# STM32H7R7xx register map
File version: 1.0
Registers are 32-bit, read-write, reset 0x0 unless marked. A register's access mark holds for its fields unless they carry their own. Offsets are from the block's base; [hi:lo] are bit positions; lines under a group give offsets from that group; {n}, {i} and the like mark numbered series.

## CRS — Clock Recovery System
Base 0x40008400
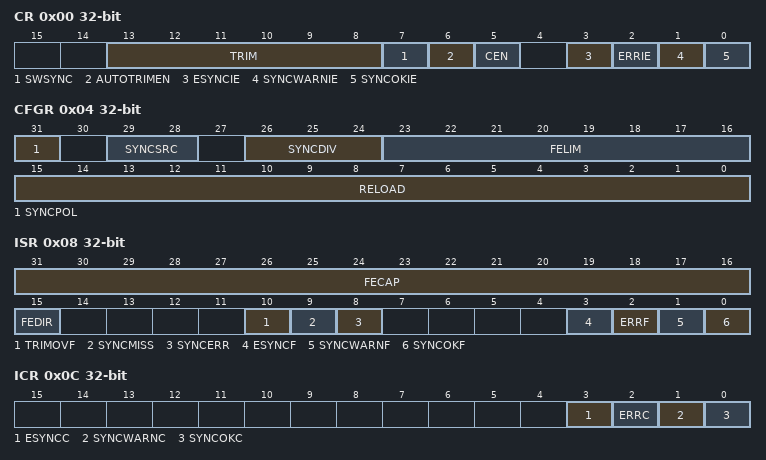
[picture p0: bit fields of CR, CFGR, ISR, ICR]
0x00 CR — CRS ccontrol register
  [13:8] TRIM — HSI48 oscillator smooth trimming
  [7] SWSYNC — Generate software SYNC event
  [6] AUTOTRIMEN — Automatic trimming enable
  [5] CEN — Frequency error counter enable
  [3] ESYNCIE — Expected SYNC interrupt enable
  [2] ERRIE — SYNC error or trimming error interrupt enable
  [1] SYNCWARNIE — SYNC warning interrupt enable
  [0] SYNCOKIE — SYNC event OK interrupt enable
0x04 CFGR — CRS configuration register
  [31] SYNCPOL — SYNC polarity selection
    0=RISING (Synchro Active on rising edge (default)); 1=FALLING (Synchro Active on falling edge)
  [29:28] SYNCSRC — SYNC signal source selection
    0=GPIO (Synchro Signal source GPIO); 1=LSE (Synchro Signal source LSE); 2=OTG_FS (Synchro Signal source OTG_FS SOF (default)); 3=OTG_HS (Synchro Signal source OTG_HS SOF)
  [26:24] SYNCDIV — SYNC divider
    0=DIV_1 (Synchro Signal not divided (default)); 1=DIV_2 (Synchro Signal divided by 2); 2=DIV_4 (Synchro Signal divided by 4); 3=DIV_8 (Synchro Signal divided by 8); 4=DIV_16 (Synchro Signal divided by 16); 5=DIV_32 (Synchro Signal divided by 32); 6=DIV_64 (Synchro Signal divided by 64); 7=DIV_128 (Synchro Signal divided by 128)
  [23:16] FELIM — Frequency error limit
  [15:0] RELOAD — Counter reload value
0x08 ISR — CRS interrupt and status register
  [31:16] FECAP — Frequency error capture
  [15] FEDIR — Frequency error direction
    0=UP (Upcounting direction, the actual frequency is above the target); 1=DOWN (Downcounting direction, the actual frequency is below the target)
  [10] TRIMOVF — Trimming overflow or underflow
  [9] SYNCMISS — SYNC missed
  [8] SYNCERR — SYNC error
  [3] ESYNCF — Expected SYNC flag
  [2] ERRF — Error flag
  [1] SYNCWARNF — SYNC warning flag
  [0] SYNCOKF — SYNC event OK flag
0x0C ICR — CRS interrupt flag clear register
  [3] ESYNCC — Expected SYNC clear flag
  [2] ERRC — Error clear flag
  [1] SYNCWARNC — SYNC warning clear flag
  [0] SYNCOKC — SYNC event OK clear flag

## MDIOS
Base 0x40009400
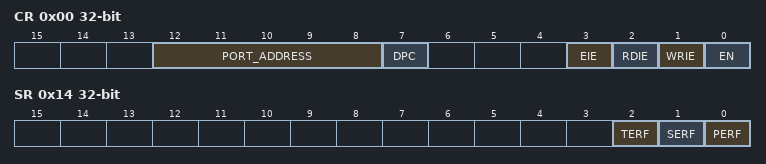
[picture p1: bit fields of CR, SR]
0x00 CR
  [12:8] PORT_ADDRESS — MDIOS slave port address mask
  [7] DPC — MDIOS slave disable preamble check
  [3] EIE — MDIOS slave register error interrupt enable
  [2] RDIE — MDIOS slave register read interrupt enable
  [1] WRIE — MDIOS slave register write interrupt enable
  [0] EN — MDIOS slave peripheral enable
0x04 WRFR
0x08 CWRFR
0x0C RDFR
0x10 CRDFR
0x14 SR
  [2] TERF — MDIOS slave preamble error flag
  [1] SERF — MDIOS slave start error flag
  [0] PERF — MDIOS slave turnaround error flag
0x18 CLRFR
{0x100+4i} DINR{i} (i=0..31)
{0x180+4i} DOUTR{i} (i=0..31)

## FDCAN_CONFIG — FD Controller Area Network Configuration
Base 0x4000A100
0x00 CKDIV — FDCAN clock divider register
  [3:0] PDIV — Input Clock Divider
0x204 OPTR — FDCAN option register
0x2F0 HWCFG — FDCAN hardware configuration register
0x2F4 VERR — FDCAN IP version register
0x2F8 IPIDR — FDCAN IP ID register
0x2FC SIDR — FDCAN size ID register

## ADC12_COMMON
Base 0x40022300
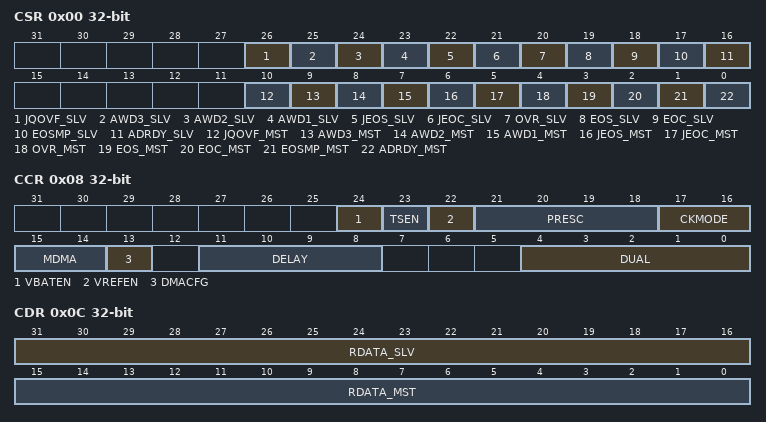
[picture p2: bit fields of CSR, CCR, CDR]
0x00 CSR — ADC common status register
  [26] JQOVF_SLV — ADC multimode slave group injected contexts queue overflow flag
  [25] AWD3_SLV — ADC multimode slave analog watchdog 3 flag
  [24] AWD2_SLV — ADC multimode slave analog watchdog 2 flag
  [23] AWD1_SLV — ADC multimode slave analog watchdog 1 flag
  [22] JEOS_SLV — ADC multimode slave group injected end of sequence conversions flag
  [21] JEOC_SLV — ADC multimode slave group injected end of unitary conversion flag
  [20] OVR_SLV — ADC multimode slave group regular overrun flag
  [19] EOS_SLV — ADC multimode slave group regular end of sequence conversions flag
  [18] EOC_SLV — ADC multimode slave group regular end of unitary conversion flag
  [17] EOSMP_SLV — ADC multimode slave group regular end of sampling flag
  [16] ADRDY_SLV — ADC multimode slave ready flag
  [10] JQOVF_MST — ADC multimode master group injected contexts queue overflow flag
  [9] AWD3_MST — ADC multimode master analog watchdog 3 flag
  [8] AWD2_MST — ADC multimode master analog watchdog 2 flag
  [7] AWD1_MST — ADC multimode master analog watchdog 1 flag
  [6] JEOS_MST — ADC multimode master group injected end of sequence conversions flag
  [5] JEOC_MST — ADC multimode master group injected end of unitary conversion flag
  [4] OVR_MST — ADC multimode master group regular overrun flag
  [3] EOS_MST — ADC multimode master group regular end of sequence conversions flag
  [2] EOC_MST — ADC multimode master group regular end of unitary conversion flag
  [1] EOSMP_MST — ADC multimode master group regular end of sampling flag
  [0] ADRDY_MST — ADC multimode master ready flag
0x08 CCR — ADC common configuration register
  [24] VBATEN — ADC internal path to battery voltage enable
  [23] TSEN — ADC internal path to temperature sensor enable
  [22] VREFEN — ADC internal path to VrefInt enable
  [21:18] PRESC — ADC common clock prescaler, only for clock source asynchronous
  [17:16] CKMODE — ADC common clock source and prescaler (prescaler only for clock source synchronous)
  [15:14] MDMA — ADC multimode DMA transfer enable
  [13] DMACFG — ADC multimode DMA transfer configuration
  [11:8] DELAY — ADC multimode delay between 2 sampling phases
    0=DELAY_1CYCLE; {v}=DELAY_{v+1}CYCLES (v=1..11)
  [4:0] DUAL — ADC multimode mode selection
    0=INDEPENDENT; 6=DUAL_REG_SIMULT; 7=DUAL_REG_INTERL; 5=DUAL_INJ_SIMULT; 9=DUAL_INJ_ALTERN; 1=DUAL_REG_SIM_INJ_SIM; 2=DUAL_REG_SIM_INJ_ALT; 3=DUAL_REG_INT_INJ_SIM
0x0C CDR — ADC common group regular data register
  [31:16] RDATA_SLV — ADC multimode slave group regular conversion data
  [15:0] RDATA_MST — ADC multimode master group regular conversion data
